# G32R430xx register map
Vendor: Geehy Semiconductor Co., Ltd.; Series: G32R4; File version: 1.0
CPU: CM52 r0p1, little endian, MPU, no FPU, DSP, VTOR, 4 interrupt priority bits
Registers are 32-bit, read-write, reset 0x0 unless marked. A register's access mark holds for its fields unless they carry their own. Offsets are from the block's base; [hi:lo] are bit positions; {n}, {i} and the like mark numbered series.

## BAKPR — Back up registers
Base 0x40003830
{0x0+4i} DR{i} (i=0..15) — Bakr data register {i}
  [15:0] DATA — Bakr data

## RTC — Real time clock
Base 0x40003A00
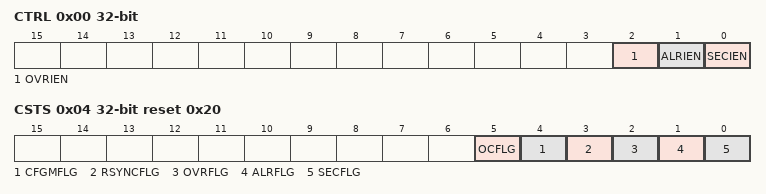
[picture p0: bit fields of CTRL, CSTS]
0x00 CTRL — Control register
  [2] OVRIEN — Overflow interrupt Enable
  [1] ALRIEN — Alarm interrupt Enable
  [0] SECIEN — Second interrupt Enable
0x04 CSTS access per field reset 0x20 — Control and State register
  [5] OCFLG ro — RTC operation OFF
  [4] CFGMFLG rw — Configuration Flag
  [3] RSYNCFLG rw — Registers Synchronized Flag
  [2] OVRFLG rw — Overflow Flag
  [1] ALRFLG rw — Alarm Flag
  [0] SECFLG rw — Second Flag
0x08 PSCRLDH wo — RTC predivision loading register High Bit
  [3:0] PSCRLDH — RTC Prescaler Load Register High
0x0C PSCRLDL wo reset 0x8000 — RTC predivision loading register Low Bit
  [15:0] PSCRLDL — RTC Prescaler Divider Register Low
0x10 DIVH ro — RTC predivider remainder register High Bit
  [3:0] PSCH — RTC prescaler divider register high
0x14 DIVL ro reset 0x8000 — RTC predivider remainder register Low Bit
  [15:0] PSCL — RTC prescaler divider register Low
0x18 CNTH — RTC count register High Bit
  [15:0] CNTH — RTC counter register high
0x1C CNTL — RTC count register Low Bit
  [15:0] CNTL — RTC counter register Low
0x20 ALRH wo reset 0xFFFF — RTC alarm clock register High Bit
  [15:0] ALRH — RTC alarm register high
0x24 ALRL wo reset 0xFFFF — RTC alarm clock register Low Bit
  [15:0] ALRL — RTC alarm register low

## LPTMR — Low-power timer
Base 0x40003B00
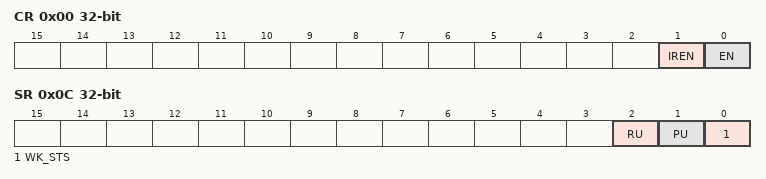
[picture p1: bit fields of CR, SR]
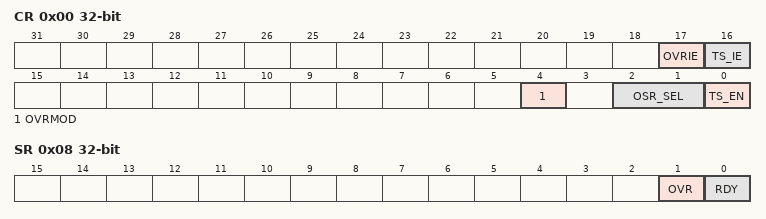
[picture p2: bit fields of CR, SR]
0x00 CR — Control register
  [1] IREN — Enable interrupt.
  [0] EN — Module enablement
0x04 PS — Prescaler register
  [3:0] PS — Prescaler divider
0x08 RV reset 0xFFFF — Reload register
  [15:0] RV — Awakening Value
0x0C SR — Status register
  [2] RU ro — Reload value update indication, automatically reset by hardware after update.
  [1] PU ro — PS value update indicator, hardware automatically resets after update.
  [0] WK_STS — Status Register, read SR register clear.

## TS — Temperature sensor
Base 0x40003C00
0x00 CR — Control register
  [17] OVRIE — TS Module Data Overflow Interrupt Enable Bit
  [16] TS_IE — Interrupt enable bit in TS module
  [4] OVRMOD — Data Overflow Control Bit
  [2:1] OSR_SEL — Sampling Rate Configuration
  [0] TS_EN — TS Module Enable Bit
0x04 DR — Data register
  [15:0] DR — DATA
0x08 SR — Status register
  [1] OVR — Overflow Flag Bit When the RDY flag bit is 1, new data is generated, and the hardware sets this bit to 1. Writing 1 to this bit in the software can clear this bit.
  [0] RDY — Sampling data valid flag, set to 1 by the hardware when the sampling data is ready. After reading the TS_DR register, this bit is automatically cleared by the hardware.

## DBGMCU — Debug support
Base 0x40005800
0x00 ID ro
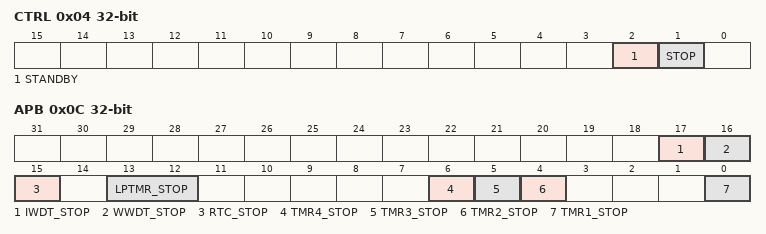
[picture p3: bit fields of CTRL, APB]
0x04 CTRL — Control Register
  [2] STANDBY — Debug Standby mode
  [1] STOP — Debug Stop mode
0x0C APB — APB Freeze Register
  [17] IWDT_STOP — Debug IWDT counter stopped when core is halted
  [16] WWDT_STOP — Debug WWDT counter stopped when core is halted
  [15] RTC_STOP — Debug RTC counter stopped when core is halted
  [13:12] LPTMR_STOP — Debug LPTMR counter stopped when core is halted
  [6] TMR4_STOP — Debug TMR4 counter stopped when core is halted
  [5] TMR3_STOP — Debug TMR3 counter stopped when core is halted
  [4] TMR2_STOP — Debug TMR2 counter stopped when core is halted
  [0] TMR1_STOP — Debug TMR1 counter stopped when core is halted

## NVIC — Nested Vectored Interrupt Controller
Base 0xE000E000
0x04 ICTR ro — Interrupt Controller Type Register
  [3:0] INTLINESNUM — Total number of interrupt lines in groups
0x100 ISER0 — Interrupt Set-Enable Register
  [31:0] SETENA
0x104 ISER1 — Interrupt Set-Enable Register
  [31:0] SETENA
0x180 ICER0 — Interrupt Clear-Enable Register
  [31:0] CLRENA
0x184 ICER1 — Interrupt Clear-Enable Register
  [31:0] CLRENA
0x200 ISPR0 — Interrupt Set-Pending Register
  [31:0] SETPEND
0x204 ISPR1 — Interrupt Set-Pending Register
  [31:0] SETPEND
0x280 ICPR0 — Interrupt Clear-Pending Register
  [31:0] CLRPEND
0x284 ICPR1 — Interrupt Clear-Pending Register
  [31:0] CLRPEND
0x300 IABR0 ro — Interrupt Active Bit Register
  [31:0] ACTIVE
0x304 IABR1 ro — Interrupt Active Bit Register
  [31:0] ACTIVE
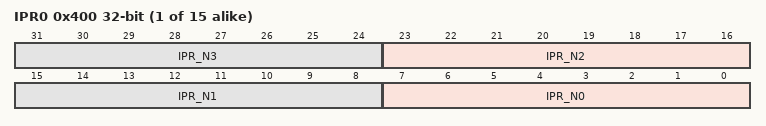
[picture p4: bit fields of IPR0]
{0x400+4i} IPR{i} (i=0..14) — Interrupt Priority Register
  [8n+7:8n] IPR_N{n} (n=0..3)
0xF00 STIR wo — Software Triggered Interrupt Register
  [8:0] INTID — interrupt to be triggered
